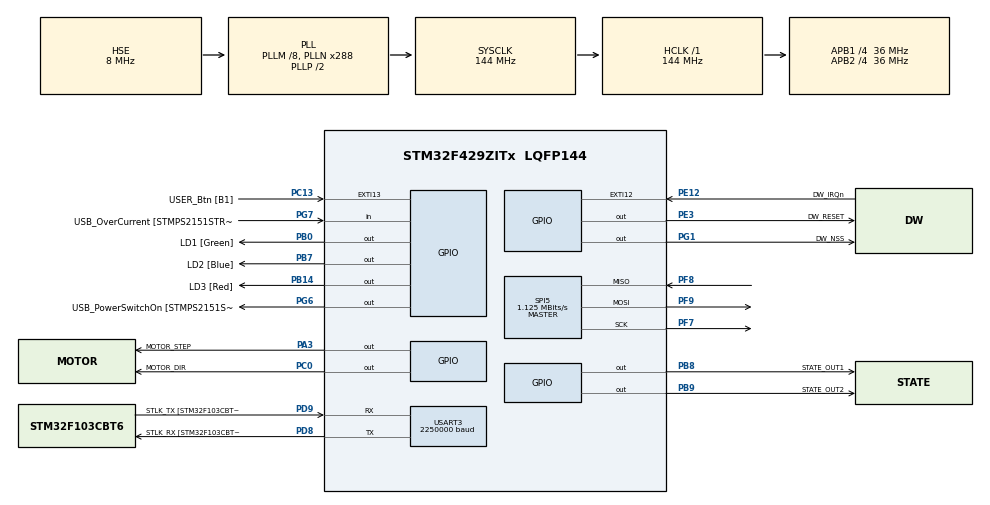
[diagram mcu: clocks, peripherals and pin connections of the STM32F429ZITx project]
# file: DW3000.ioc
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Mcu.Family=STM32F4
Mcu.Name=STM32F429ZITx
Mcu.Package=LQFP144
NVIC.EXTI15_10_IRQn=true\:0\:0\:false\:false\:true\:true\:true\:true
NVIC.PriorityGroup=NVIC_PRIORITYGROUP_4
NVIC.USART3_IRQn=true\:0\:0\:false\:false\:true\:true\:true\:true
PA1.GPIO_Label=RMII_REF_CLK [LAN8742A-CZ-TR_REFCLK0]
PA1.Signal=ETH_REF_CLK
PA10.GPIO_Label=USB_ID
PA10.Signal=USB_OTG_FS_ID
PA11.GPIO_Label=USB_DM
PA11.Signal=USB_OTG_FS_DM
PA12.GPIO_Label=USB_DP
PA12.Signal=USB_OTG_FS_DP
PA13.GPIO_Label=TMS
PA13.Signal=SYS_JTMS-SWDIO
PA14.GPIO_Label=TCK
PA14.Signal=SYS_JTCK-SWCLK
PA2.GPIO_Label=RMII_MDIO [LAN8742A-CZ-TR_MDIO]
PA2.Signal=ETH_MDIO
PA3.GPIO_Label=MOTOR_STEP
PA3.Signal=GPIO_Output
PA8.GPIO_Label=USB_SOF [TP1]
PA8.Signal=USB_OTG_FS_SOF
PA9.GPIO_Label=USB_VBUS
PA9.Signal=USB_OTG_FS_VBUS
PB0.GPIO_Label=LD1 [Green]
PB0.Signal=GPIO_Output
PB13.GPIO_Label=RMII_TXD1 [LAN8742A-CZ-TR_TXD1]
PB13.Signal=ETH_TXD1
PB14.GPIO_Label=LD3 [Red]
PB14.Signal=GPIO_Output
PB7.GPIO_Label=LD2 [Blue]
PB7.Signal=GPIO_Output
PB8.GPIO_Label=STATE_OUT1
PB8.Signal=GPIO_Output
PB9.GPIO_Label=STATE_OUT2
PB9.Signal=GPIO_Output
PC0.GPIO_Label=MOTOR_DIR
PC0.Signal=GPIO_Output
PC1.GPIO_Label=RMII_MDC [LAN8742A-CZ-TR_MDC]
PC1.Signal=ETH_MDC
PC13.GPIO_Label=USER_Btn [B1]
PC13.Signal=GPXTI13
PC14/OSC32_IN.Mode=LSE-External-Oscillator
PC14/OSC32_IN.Signal=RCC_OSC32_IN
PC15/OSC32_OUT.Mode=LSE-External-Oscillator
PC15/OSC32_OUT.Signal=RCC_OSC32_OUT
PC4.GPIO_Label=RMII_RXD0 [LAN8742A-CZ-TR_RXD0]
PC4.Signal=ETH_RXD0
PC5.GPIO_Label=RMII_RXD1 [LAN8742A-CZ-TR_RXD1]
PC5.Signal=ETH_RXD1
PD8.GPIO_Label=STLK_RX [STM32F103CBT6_PA3]
PD8.Mode=Asynchronous
PD8.Signal=USART3_TX
PD9.GPIO_Label=STLK_TX [STM32F103CBT6_PA2]
PD9.Mode=Asynchronous
PD9.Signal=USART3_RX
PE12.GPIO_Label=DW_IRQn
PE12.GPIO_PuPd=GPIO_PULLDOWN
PE12.Signal=GPXTI12
PE3.GPIO_Label=DW_RESET
PE3.GPIO_ModeDefaultOutputPP=GPIO_MODE_OUTPUT_OD
PE3.GPIO_PuPd=GPIO_NOPULL
PE3.Signal=GPIO_Output
PF7.Mode=Full_Duplex_Master
PF7.Signal=SPI5_SCK
PF8.Mode=Full_Duplex_Master
PF8.Signal=SPI5_MISO
PF9.Mode=Full_Duplex_Master
PF9.Signal=SPI5_MOSI
PG1.GPIO_Label=DW_NSS
PG1.PinState=GPIO_PIN_SET
PG1.Signal=GPIO_Output
PG11.GPIO_Label=RMII_TX_EN [LAN8742A-CZ-TR_TXEN]
PG11.Signal=ETH_TX_EN
PG13.GPIO_Label=RMII_TXD0 [LAN8742A-CZ-TR_TXD0]
PG13.Signal=ETH_TXD0
PG6.GPIO_Label=USB_PowerSwitchOn [STMPS2151STR_EN]
PG6.Signal=GPIO_Output
PG7.GPIO_Label=USB_OverCurrent [STMPS2151STR_FAULT]
PG7.Signal=GPIO_Input
PH0/OSC_IN.GPIO_Label=MCO [STM32F103CBT6_PA8]
PH0/OSC_IN.Mode=HSE-External-Clock-Source
PH0/OSC_IN.Signal=RCC_OSC_IN
PH1/OSC_OUT.Mode=HSE-External-Clock-Source
PH1/OSC_OUT.Signal=RCC_OSC_OUT
ProjectManager.HeapSize=0x200
ProjectManager.StackSize=0x400
ProjectManager.TargetToolchain=STM32CubeIDE
RCC.48MHZClocksFreq_Value=72000000
RCC.AHBFreq_Value=144000000
RCC.APB1CLKDivider=RCC_HCLK_DIV4
RCC.APB1Freq_Value=36000000
RCC.APB1TimFreq_Value=72000000
RCC.APB2CLKDivider=RCC_HCLK_DIV4
RCC.APB2Freq_Value=36000000
RCC.APB2TimFreq_Value=72000000
RCC.CortexFreq_Value=144000000
RCC.HCLKFreq_Value=144000000
RCC.HSE_VALUE=8000000
RCC.HSI_VALUE=16000000
RCC.PLLM=8
RCC.PLLMUL=RCC_PLL_MUL9
RCC.PLLN=288
RCC.PLLSourceVirtual=RCC_PLLSOURCE_HSE
RCC.PRESCALERUSB=RCC_USBCLKSOURCE_PLL_DIV1_5
RCC.SYSCLKFreq_VALUE=144000000
RCC.SYSCLKSource=RCC_SYSCLKSOURCE_PLLCLK
RCC.SYSCLKSourceVirtual=RCC_SYSCLKSOURCE_PLLCLK
RCC.USBFreq_Value=48000000
RCC.VCOOutputFreq_Value=288000000
SPI5.BaudRatePrescaler=SPI_BAUDRATEPRESCALER_32
SPI5.CalculateBaudRate=1.125 MBits/s
SPI5.Direction=SPI_DIRECTION_2LINES
SPI5.Mode=SPI_MODE_MASTER
SPI5.VirtualType=VM_MASTER
USART3.BaudRate=2250000
USART3.VirtualMode=VM_ASYNC
board=NUCLEO-F429ZI

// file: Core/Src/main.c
/* USER CODE BEGIN Header */
/**
  ******************************************************************************
  * @file           : main.c
  * @brief          : Main program body
  ******************************************************************************
  * @attention
  *
  * Copyright (c) 2022 STMicroelectronics.
  * All rights reserved.
  *
  * This software is licensed under terms that can be found in the LICENSE file
  * in the root directory of this software component.
  * If no LICENSE file comes with this software, it is provided AS-IS.
  *
  ******************************************************************************
  */
/* USER CODE END Header */
#include "main.h"

/* USER CODE BEGIN Includes */
#include "port.h"
#include "uart_stdio.h"
#include "apps/applications.h"
/* USER CODE END Includes */

 SPI_HandleTypeDef hspi5;

UART_HandleTypeDef huart3;

void SystemClock_Config(void);
static void MX_GPIO_Init(void);
static void MX_USART3_UART_Init(void);
static void MX_SPI5_Init(void);

int main(void)
{

  /* MCU Configuration--------------------------------------------------------*/

  /* Reset of all peripherals, Initializes the Flash interface and the Systick. */
  HAL_Init();

  /* Configure the system clock */
  SystemClock_Config();

  /* Initialize all configured peripherals */
  MX_GPIO_Init();
  MX_USART3_UART_Init();
  MX_SPI5_Init();
  /* USER CODE BEGIN 2 */

  /* ----- Setup DW3000, USART and start main application ----- */

  /* DW3000 will be configured and enabled later, if necessary, but CubeMX has
   * no option to generate code without enabling the interrupt. */
  HAL_NVIC_DisableIRQ(EXTI15_10_IRQn);

  /*
   * DW_RESET_Pin has been configured by CubeMx as Exti0 line
   * Reconfigure the line as Input
   */
  setup_DWICRSTnIRQ(0);

  stdio_init(&huart3);

  dw_main();

  /* USER CODE END 2 */

  /* Infinite loop */
  while (1)
  {

  }
}

void SystemClock_Config(void)
{
  RCC_OscInitTypeDef RCC_OscInitStruct = {0};
  RCC_ClkInitTypeDef RCC_ClkInitStruct = {0};

  /** Configure the main internal regulator output voltage
  */
  __HAL_RCC_PWR_CLK_ENABLE();
  __HAL_PWR_VOLTAGESCALING_CONFIG(PWR_REGULATOR_VOLTAGE_SCALE1);

  /** Initializes the RCC Oscillators according to the specified parameters
  * in the RCC_OscInitTypeDef structure.
  */
  RCC_OscInitStruct.OscillatorType = RCC_OSCILLATORTYPE_HSE;
  RCC_OscInitStruct.HSEState = RCC_HSE_BYPASS;
  RCC_OscInitStruct.PLL.PLLState = RCC_PLL_ON;
  RCC_OscInitStruct.PLL.PLLSource = RCC_PLLSOURCE_HSE;
  RCC_OscInitStruct.PLL.PLLM = 8;
  RCC_OscInitStruct.PLL.PLLN = 288;
  RCC_OscInitStruct.PLL.PLLP = RCC_PLLP_DIV2;
  RCC_OscInitStruct.PLL.PLLQ = 4;
  if (HAL_RCC_OscConfig(&RCC_OscInitStruct) != HAL_OK)
  {
    Error_Handler();
  }

  /** Initializes the CPU, AHB and APB buses clocks
  */
  RCC_ClkInitStruct.ClockType = RCC_CLOCKTYPE_HCLK|RCC_CLOCKTYPE_SYSCLK
                              |RCC_CLOCKTYPE_PCLK1|RCC_CLOCKTYPE_PCLK2;
  RCC_ClkInitStruct.SYSCLKSource = RCC_SYSCLKSOURCE_PLLCLK;
  RCC_ClkInitStruct.AHBCLKDivider = RCC_SYSCLK_DIV1;
  RCC_ClkInitStruct.APB1CLKDivider = RCC_HCLK_DIV4;
  RCC_ClkInitStruct.APB2CLKDivider = RCC_HCLK_DIV4;

  if (HAL_RCC_ClockConfig(&RCC_ClkInitStruct, FLASH_LATENCY_4) != HAL_OK)
  {
    Error_Handler();
  }
}

static void MX_SPI5_Init(void)
{

  /* SPI5 parameter configuration*/
  hspi5.Instance = SPI5;
  hspi5.Init.Mode = SPI_MODE_MASTER;
  hspi5.Init.Direction = SPI_DIRECTION_2LINES;
  hspi5.Init.DataSize = SPI_DATASIZE_8BIT;
  hspi5.Init.CLKPolarity = SPI_POLARITY_LOW;
  hspi5.Init.CLKPhase = SPI_PHASE_1EDGE;
  hspi5.Init.NSS = SPI_NSS_SOFT;
  hspi5.Init.BaudRatePrescaler = SPI_BAUDRATEPRESCALER_32;
  hspi5.Init.FirstBit = SPI_FIRSTBIT_MSB;
  hspi5.Init.TIMode = SPI_TIMODE_DISABLE;
  hspi5.Init.CRCCalculation = SPI_CRCCALCULATION_DISABLE;
  hspi5.Init.CRCPolynomial = 10;
  if (HAL_SPI_Init(&hspi5) != HAL_OK)
  {
    Error_Handler();
  }

}

static void MX_USART3_UART_Init(void)
{

  huart3.Instance = USART3;
  huart3.Init.BaudRate = 2250000;
  huart3.Init.WordLength = UART_WORDLENGTH_8B;
  huart3.Init.StopBits = UART_STOPBITS_1;
  huart3.Init.Parity = UART_PARITY_NONE;
  huart3.Init.Mode = UART_MODE_TX_RX;
  huart3.Init.HwFlowCtl = UART_HWCONTROL_NONE;
  huart3.Init.OverSampling = UART_OVERSAMPLING_16;
  if (HAL_UART_Init(&huart3) != HAL_OK)
  {
    Error_Handler();
  }

}

static void MX_GPIO_Init(void)
{
  GPIO_InitTypeDef GPIO_InitStruct = {0};

  /* GPIO Ports Clock Enable */
  __HAL_RCC_GPIOE_CLK_ENABLE();
  __HAL_RCC_GPIOC_CLK_ENABLE();
  __HAL_RCC_GPIOF_CLK_ENABLE();
  __HAL_RCC_GPIOH_CLK_ENABLE();
  __HAL_RCC_GPIOA_CLK_ENABLE();
  __HAL_RCC_GPIOB_CLK_ENABLE();
  __HAL_RCC_GPIOG_CLK_ENABLE();
  __HAL_RCC_GPIOD_CLK_ENABLE();

  /*Configure GPIO pin Output Level */
  HAL_GPIO_WritePin(DW_RESET_GPIO_Port, DW_RESET_Pin, GPIO_PIN_RESET);

  /*Configure GPIO pin Output Level */
  HAL_GPIO_WritePin(MOTOR_DIR_GPIO_Port, MOTOR_DIR_Pin, GPIO_PIN_RESET);

  /*Configure GPIO pin Output Level */
  HAL_GPIO_WritePin(MOTOR_STEP_GPIO_Port, MOTOR_STEP_Pin, GPIO_PIN_RESET);

  /*Configure GPIO pin Output Level */
  HAL_GPIO_WritePin(GPIOB, LD1_Pin|LD3_Pin|LD2_Pin|STATE_OUT1_Pin
                          |STATE_OUT2_Pin, GPIO_PIN_RESET);

  /*Configure GPIO pin Output Level */
  HAL_GPIO_WritePin(DW_NSS_GPIO_Port, DW_NSS_Pin, GPIO_PIN_SET);

  /*Configure GPIO pin Output Level */
  HAL_GPIO_WritePin(USB_PowerSwitchOn_GPIO_Port, USB_PowerSwitchOn_Pin, GPIO_PIN_RESET);

  /*Configure GPIO pin : DW_RESET_Pin */
  GPIO_InitStruct.Pin = DW_RESET_Pin;
  GPIO_InitStruct.Mode = GPIO_MODE_OUTPUT_OD;
  GPIO_InitStruct.Pull = GPIO_NOPULL;
  GPIO_InitStruct.Speed = GPIO_SPEED_FREQ_LOW;
  HAL_GPIO_Init(DW_RESET_GPIO_Port, &GPIO_InitStruct);

  /*Configure GPIO pin : USER_Btn_Pin */
  GPIO_InitStruct.Pin = USER_Btn_Pin;
  GPIO_InitStruct.Mode = GPIO_MODE_IT_RISING;
  GPIO_InitStruct.Pull = GPIO_NOPULL;
  HAL_GPIO_Init(USER_Btn_GPIO_Port, &GPIO_InitStruct);

  /*Configure GPIO pin : MOTOR_DIR_Pin */
  GPIO_InitStruct.Pin = MOTOR_DIR_Pin;
  GPIO_InitStruct.Mode = GPIO_MODE_OUTPUT_PP;
  GPIO_InitStruct.Pull = GPIO_NOPULL;
  GPIO_InitStruct.Speed = GPIO_SPEED_FREQ_LOW;
  HAL_GPIO_Init(MOTOR_DIR_GPIO_Port, &GPIO_InitStruct);

  /*Configure GPIO pins : RMII_MDC_Pin RMII_RXD0_Pin RMII_RXD1_Pin */
  GPIO_InitStruct.Pin = RMII_MDC_Pin|RMII_RXD0_Pin|RMII_RXD1_Pin;
  GPIO_InitStruct.Mode = GPIO_MODE_AF_PP;
  GPIO_InitStruct.Pull = GPIO_NOPULL;
  GPIO_InitStruct.Speed = GPIO_SPEED_FREQ_VERY_HIGH;
  GPIO_InitStruct.Alternate = GPIO_AF11_ETH;
  HAL_GPIO_Init(GPIOC, &GPIO_InitStruct);

  /*Configure GPIO pins : RMII_REF_CLK_Pin RMII_MDIO_Pin */
  GPIO_InitStruct.Pin = RMII_REF_CLK_Pin|RMII_MDIO_Pin;
  GPIO_InitStruct.Mode = GPIO_MODE_AF_PP;
  GPIO_InitStruct.Pull = GPIO_NOPULL;
  GPIO_InitStruct.Speed = GPIO_SPEED_FREQ_VERY_HIGH;
  GPIO_InitStruct.Alternate = GPIO_AF11_ETH;
  HAL_GPIO_Init(GPIOA, &GPIO_InitStruct);

  /*Configure GPIO pin : MOTOR_STEP_Pin */
  GPIO_InitStruct.Pin = MOTOR_STEP_Pin;
  GPIO_InitStruct.Mode = GPIO_MODE_OUTPUT_PP;
  GPIO_InitStruct.Pull = GPIO_NOPULL;
  GPIO_InitStruct.Speed = GPIO_SPEED_FREQ_LOW;
  HAL_GPIO_Init(MOTOR_STEP_GPIO_Port, &GPIO_InitStruct);

  /*Configure GPIO pins : LD1_Pin LD3_Pin LD2_Pin STATE_OUT1_Pin
                           STATE_OUT2_Pin */
  GPIO_InitStruct.Pin = LD1_Pin|LD3_Pin|LD2_Pin|STATE_OUT1_Pin
                          |STATE_OUT2_Pin;
  GPIO_InitStruct.Mode = GPIO_MODE_OUTPUT_PP;
  GPIO_InitStruct.Pull = GPIO_NOPULL;
  GPIO_InitStruct.Speed = GPIO_SPEED_FREQ_LOW;
  HAL_GPIO_Init(GPIOB, &GPIO_InitStruct);

  /*Configure GPIO pins : DW_NSS_Pin USB_PowerSwitchOn_Pin */
  GPIO_InitStruct.Pin = DW_NSS_Pin|USB_PowerSwitchOn_Pin;
  GPIO_InitStruct.Mode = GPIO_MODE_OUTPUT_PP;
  GPIO_InitStruct.Pull = GPIO_NOPULL;
  GPIO_InitStruct.Speed = GPIO_SPEED_FREQ_LOW;
  HAL_GPIO_Init(GPIOG, &GPIO_InitStruct);

  /*Configure GPIO pin : DW_IRQn_Pin */
  GPIO_InitStruct.Pin = DW_IRQn_Pin;
  GPIO_InitStruct.Mode = GPIO_MODE_IT_RISING;
  GPIO_InitStruct.Pull = GPIO_PULLDOWN;
  HAL_GPIO_Init(DW_IRQn_GPIO_Port, &GPIO_InitStruct);

  /*Configure GPIO pin : RMII_TXD1_Pin */
  GPIO_InitStruct.Pin = RMII_TXD1_Pin;
  GPIO_InitStruct.Mode = GPIO_MODE_AF_PP;
  GPIO_InitStruct.Pull = GPIO_NOPULL;
  GPIO_InitStruct.Speed = GPIO_SPEED_FREQ_VERY_HIGH;
  GPIO_InitStruct.Alternate = GPIO_AF11_ETH;
  HAL_GPIO_Init(RMII_TXD1_GPIO_Port, &GPIO_InitStruct);

  /*Configure GPIO pin : USB_OverCurrent_Pin */
  GPIO_InitStruct.Pin = USB_OverCurrent_Pin;
  GPIO_InitStruct.Mode = GPIO_MODE_INPUT;
  GPIO_InitStruct.Pull = GPIO_NOPULL;
  HAL_GPIO_Init(USB_OverCurrent_GPIO_Port, &GPIO_InitStruct);

  /*Configure GPIO pins : USB_SOF_Pin USB_ID_Pin USB_DM_Pin USB_DP_Pin */
  GPIO_InitStruct.Pin = USB_SOF_Pin|USB_ID_Pin|USB_DM_Pin|USB_DP_Pin;
  GPIO_InitStruct.Mode = GPIO_MODE_AF_PP;
  GPIO_InitStruct.Pull = GPIO_NOPULL;
  GPIO_InitStruct.Speed = GPIO_SPEED_FREQ_VERY_HIGH;
  GPIO_InitStruct.Alternate = GPIO_AF10_OTG_FS;
  HAL_GPIO_Init(GPIOA, &GPIO_InitStruct);

  /*Configure GPIO pin : USB_VBUS_Pin */
  GPIO_InitStruct.Pin = USB_VBUS_Pin;
  GPIO_InitStruct.Mode = GPIO_MODE_INPUT;
  GPIO_InitStruct.Pull = GPIO_NOPULL;
  HAL_GPIO_Init(USB_VBUS_GPIO_Port, &GPIO_InitStruct);

  /*Configure GPIO pins : RMII_TX_EN_Pin RMII_TXD0_Pin */
  GPIO_InitStruct.Pin = RMII_TX_EN_Pin|RMII_TXD0_Pin;
  GPIO_InitStruct.Mode = GPIO_MODE_AF_PP;
  GPIO_InitStruct.Pull = GPIO_NOPULL;
  GPIO_InitStruct.Speed = GPIO_SPEED_FREQ_VERY_HIGH;
  GPIO_InitStruct.Alternate = GPIO_AF11_ETH;
  HAL_GPIO_Init(GPIOG, &GPIO_InitStruct);

  /* EXTI interrupt init*/
  HAL_NVIC_SetPriority(EXTI15_10_IRQn, 0, 0);
  HAL_NVIC_EnableIRQ(EXTI15_10_IRQn);

}

void Error_Handler(void)
{
  __disable_irq();
  while (1)
  {
  }
}
